# neorv32 register map
Vendor: github.com/stnolting/neorv32; Series: RISC-V; File version: 1.12.8
CPU: other r1p0, little endian, MPU, FPU, I-cache, D-cache, ITCM, DTCM, 4 interrupt priority bits
Address unit: 16 bits
Registers are 32-bit, read-write, reset 0x0 unless marked. A register's access mark holds for its fields unless they carry their own. Offsets are from the block's base; [hi:lo] are bit positions.

## TRACER — Execution Trace Buffer
Base 0xFFF30000
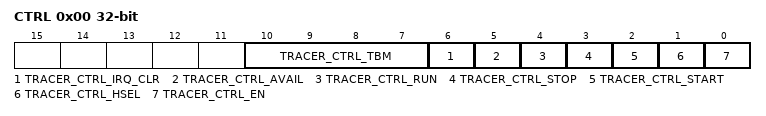
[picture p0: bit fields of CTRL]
0x00 CTRL — Control and status register
  [10:7] TRACER_CTRL_TBM ro — log2 of trace buffer depth
  [6] TRACER_CTRL_IRQ_CLR wo — Clear pending interrupt when writing 1
  [5] TRACER_CTRL_AVAIL ro — Trace data available when set
  [4] TRACER_CTRL_RUN ro — Tracing in progress when set
  [3] TRACER_CTRL_STOP wo — Manually stop tracing, flag always reads as zero
  [2] TRACER_CTRL_START wo — Start tracing, flag always reads as zero
  [1] TRACER_CTRL_HSEL — Hart select for tracing
  [0] TRACER_CTRL_EN — TRACER enable, reset module when 0
0x04 STOP_ADDR — Stop tracing when reaching this address, set to all-zero to disable auto-stopping
0x08 DELTA_SRC ro — Trace data: delta source address + first-packet bit
0x0C DELTA_DST ro read-modifies — Trace data: delta destination address + trap-entry bit

## SYSINFO — System configuration information memory
Base 0xFFFE0000
0x00 CLK — Processor clock speed in Hz
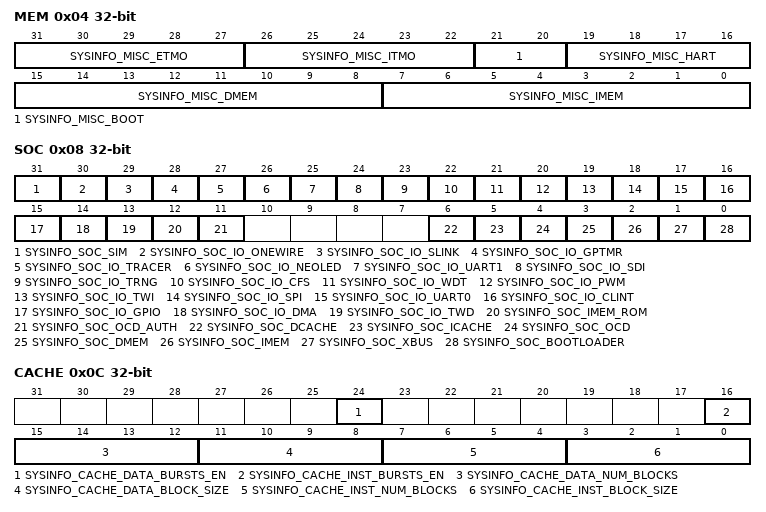
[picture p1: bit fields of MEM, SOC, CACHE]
0x04 MEM ro — Miscellaneous system configurations
  [31:27] SYSINFO_MISC_ETMO — log2(external bus timeout cycles)
  [26:22] SYSINFO_MISC_ITMO — log2(internal bus timeout cycles)
  [21:20] SYSINFO_MISC_BOOT — Boot mode configuration select
  [19:16] SYSINFO_MISC_HART — Number of physical CPU cores
  [15:8] SYSINFO_MISC_DMEM — log2(DMEM size in bytes)
  [7:0] SYSINFO_MISC_IMEM — log2(IMEM size in bytes)
0x08 SOC ro — SoC configuration
  [31] SYSINFO_SOC_SIM — Set if this is a simulation
  [30] SYSINFO_SOC_IO_ONEWIRE — 1-wire interface controller implemented
  [29] SYSINFO_SOC_IO_SLINK — Stream link interface implemented
  [28] SYSINFO_SOC_IO_GPTMR — General purpose timer implemented
  [27] SYSINFO_SOC_IO_TRACER — Execution tracer implemented
  [26] SYSINFO_SOC_IO_NEOLED — NeoPixel-compatible smart LED interface implemented
  [25] SYSINFO_SOC_IO_UART1 — Secondary universal asynchronous receiver/transmitter implemented
  [24] SYSINFO_SOC_IO_SDI — Serial data interface implemented
  [23] SYSINFO_SOC_IO_TRNG — True random number generator implemented
  [22] SYSINFO_SOC_IO_CFS — Custom functions subsystem implemented
  [21] SYSINFO_SOC_IO_WDT — Watchdog timer implemented
  [20] SYSINFO_SOC_IO_PWM — Pulse-width modulation unit implemented
  [19] SYSINFO_SOC_IO_TWI — Two-wire interface implemented
  [18] SYSINFO_SOC_IO_SPI — Serial peripheral interface implemented
  [17] SYSINFO_SOC_IO_UART0 — Primary universal asynchronous receiver/transmitter implemented
  [16] SYSINFO_SOC_IO_CLINT — Core local interruptor implemented
  [15] SYSINFO_SOC_IO_GPIO — General purpose input/output port unit implemented
  [14] SYSINFO_SOC_IO_DMA — Direct memory access controller implemented
  [13] SYSINFO_SOC_IO_TWD — Two-wire device implemented
  [12] SYSINFO_SOC_IMEM_ROM — Processor-internal instruction memory implemented as pre-initialized ROM
  [11] SYSINFO_SOC_OCD_AUTH — On-chip debugger authentication implemented
  [6] SYSINFO_SOC_DCACHE — Processor-internal data cache implemented
  [5] SYSINFO_SOC_ICACHE — Processor-internal instruction cache implemented
  [4] SYSINFO_SOC_OCD — On-chip debugger implemented
  [3] SYSINFO_SOC_DMEM — Processor-internal data memory implemented
  [2] SYSINFO_SOC_IMEM — Processor-internal instruction memory implemented
  [1] SYSINFO_SOC_XBUS — External bus interface implemented
  [0] SYSINFO_SOC_BOOTLOADER — Bootloader implemented
0x0C CACHE ro — Cache configuration
  [24] SYSINFO_CACHE_DATA_BURSTS_EN — d-cache: burst transfers enabled
  [16] SYSINFO_CACHE_INST_BURSTS_EN — i-cache: burst transfers enabled
  [15:12] SYSINFO_CACHE_DATA_NUM_BLOCKS — d-cache: log2(Number of cache blocks)
  [11:8] SYSINFO_CACHE_DATA_BLOCK_SIZE — d-cache: log2(Block size in bytes)
  [7:4] SYSINFO_CACHE_INST_NUM_BLOCKS — i-cache: log2(Number of cache blocks)
  [3:0] SYSINFO_CACHE_INST_BLOCK_SIZE — i-cache: log2(Block size in bytes)
